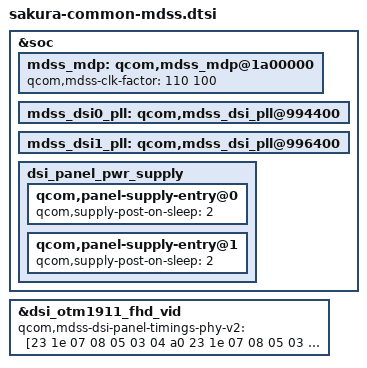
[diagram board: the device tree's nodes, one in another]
/* msm8953-mdss */
&soc {
	mdss_mdp: qcom,mdss_mdp@1a00000 {
			qcom,mdss-clk-factor = <110 100>;	/* 1.10 times */
	};
};

/* msm8953-mdss-pll */
&soc {
	mdss_dsi0_pll: qcom,mdss_dsi_pll@994400 {
		/delete-property/ qcom,dsi-pll-ssc-en;
		/delete-property/ qcom,dsi-pll-ssc-mode;
	};
	mdss_dsi1_pll: qcom,mdss_dsi_pll@996400 {
		/delete-property/ qcom,dsi-pll-ssc-en;
		/delete-property/ qcom,dsi-pll-ssc-mode;
	};
};

/* msm8953-mdss-panels */
#include "panel/dsi-panel-otm1911-fhd-video.dtsi"
#include "../common/panel/dsi-panel-otm1911-fhdplus-video.dtsi"
#include "../common/panel/dsi-panel-ili7807-fhdplus-video.dtsi"
#include "../common/panel/dsi-panel-hx8399c-fhdplus-video.dtsi"

&soc {
	dsi_panel_pwr_supply: dsi_panel_pwr_supply {
		qcom,panel-supply-entry@0 {
			qcom,supply-post-on-sleep= <2>;
		};
		qcom,panel-supply-entry@1 {
			qcom,supply-post-on-sleep= <2>;
		};
	};
};


&dsi_otm1911_fhd_vid {
	qcom,mdss-dsi-panel-timings-phy-v2 = [23 1e 07 08 05 03 04 a0
		23 1e 07 08 05 03 04 a0
		23 1e 07 08 05 03 04 a0
		23 1e 07 08 05 03 04 a0
		23 18 07 08 05 03 04 a0];
};
